# SMS register map
Vendor: Texas Instruments
Peripheral module from a debugger description file (folder omap36xx).
Registers are 32-bit, read-write, reset values left out (the file's numbers can be read two ways) unless marked. A register's access mark holds for its fields unless they carry their own. Offsets are as the file gives them; lines under a group give offsets from that group; [hi:lo] are bit positions; {n}, {i} and the like mark numbered series; 'fields as' and 'values as' point back to an identical list; <NAME> marks a mode.

## SMS
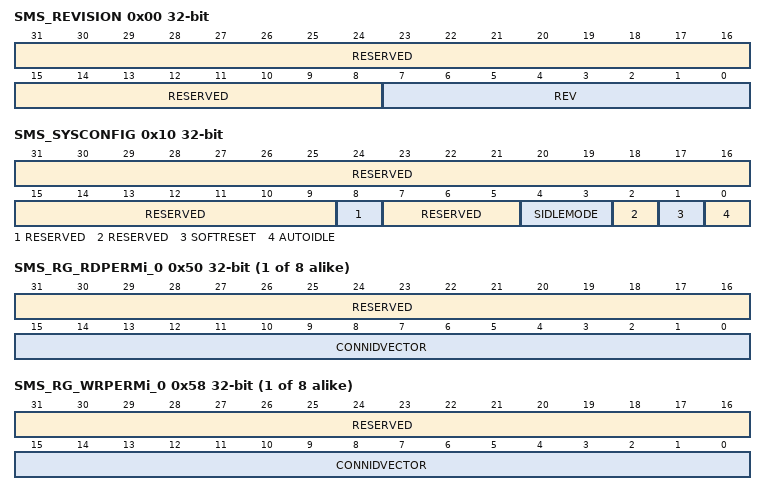
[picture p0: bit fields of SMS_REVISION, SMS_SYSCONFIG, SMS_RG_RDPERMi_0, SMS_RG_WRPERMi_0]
0x00 SMS_REVISION ro — This register contains the IP revision code. IP revision code is defined at design time
  [31:8] RESERVED — Read returns 0.
  [7:0] REV — IP revision code[7:4] Major revision[3:0] Minor revisionExamples: 0x10 for 1.0, 0x21 for 2.1
0x10 SMS_SYSCONFIG — This register controls the various parameters of the Interconnect.
  [31:9] RESERVED — Write 0s for future compatibility. Read returns 0s.
  [8] RESERVED — Write 0s for future compatibility. Read returns 0s.
  [7:5] RESERVED — Write 0s for future compatibility. Read returns 0s.
  [4:3] SIDLEMODE — Power management Req/Ack Control
    0=Force Idle - An idle request is acknowledged unconditionally; 1=No Idle - An idle request is never acknowledged; 2=Smart Idle - Acknowledgment to an idle request is based on the internal activity of the module; 3=Reserved - Do not use
  [2] RESERVED — Write 0s for future compatibility. Read returns 0.
  [1] SOFTRESET — Software reset
    0=Normal mode (no reset applied); 1=Software reset is activated
  [0] AUTOIDLE — Internal interface clock gating strategy
    0=Interface clock is free-running; 1=Automatic interface clock gating strategy is applied, based on the interconnect activity
0x14 SMS_SYSSTATUS ro — This register provides module status, excluding interrupt status info.
  [0] RESETDONE — Internal reset monitoring
    0=Internal module reset is ongoing; 1=Reset complete. The module is ready to be used.
{0x48+0x20*i} SMS_RG_ATTi_{i} (i=0..7) — Request information permission
  [31:0] REQINFO — Request information permissionThe REQINFO field is a bit vector of permissions, one per MReqInfo encoding: NonHost/Host - User/Supervisor - Functional/Debug - Data Transfer/Opcode Fetch
{0x50+0x20*i} SMS_RG_RDPERMi_{i} (i=0..7) — This register provides the list of all initiators that have permission for reading from that memory region.
  [31:16] RESERVED — Write 0s for future compatibility. Read returns 0s.
  [15:0] CONNIDVECTOR — One bit per initiator group. Bit 0 set to 1 means that initiator whose ConnID = 0 has read permission to the protected region i.
{0x58+0x20*i} SMS_RG_WRPERMi_{i} (i=0..7) — This register provides the list of all initiators that have permission for writing to that memory region.
  [31:16] RESERVED — Write 0s for future compatibility. Read returns 0s.
  [15:0] CONNIDVECTOR — One bit per initiator group. Bit 0 set to 1 means that initiator whose ConnID = 0 has write permission to the protected region i.
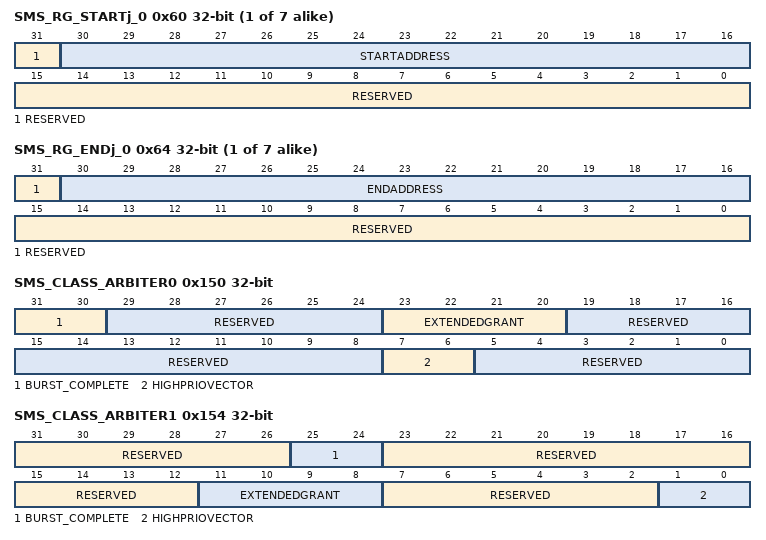
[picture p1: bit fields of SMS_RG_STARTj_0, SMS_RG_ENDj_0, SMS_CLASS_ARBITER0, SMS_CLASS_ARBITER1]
{0x60+0x20*i} SMS_RG_STARTj_{i} (i=0..6) — This register provides the region #j start address (lowest address inside the region), with a 64-KB granularity.
  [31] RESERVED — Write 0s for future compatibility. Read returns 0.
  [30:16] STARTADDRESS — Region #j start address (included in the region)Aligned on 64-KB boundary. [15:0] must be written with 0s. No STARTADDRESS parameter for region 0.
  [15:0] RESERVED — Write 0s for future compatibility. Read returns 0.
{0x64+0x20*i} SMS_RG_ENDj_{i} (i=0..6) — This register provides the region #j end address (lowest address outside the region), with a 64-KB granularity.
  [31] RESERVED — Write 0s for future compatibility. Read returns 0s.
  [30:16] ENDADDRESS — Region #j end address (not included in the region)Aligned on 64-KB boundary. [15:0] must be written with 0s. No ENDADDRESS parameter for region 0.
  [15:0] RESERVED — Write 0s for future compatibility. Read returns 0s.
0x150 SMS_CLASS_ARBITER0 — This register controls the arbitration parameters between the class 0 request groups.
  [31:30] BURST_COMPLETE — Delayed service until burst request complete BurstComplete[k], k= 6 to 7 (BURST-COMPLETE[30] is for group number 6, BURST-COMPLETE[31] is for group number 7)
    0=BURST-COMPLETE_0 (Group #k request to arbiter issued as soon as the first burst request is available); 1=BURST-COMPLETE_1 (Group #k request to arbiter delayed until a complete burst transaction is buffered)
  [29:24] RESERVED — Write 0s for future compatibility. Read returns 0s.
  [23:20] EXTENDEDGRANT — Extended grant service inside a classVector specifying the number of consecutive services a group is granted. 2 bits per group ExtendedGrant[2*k+1,2*k], k = 6 to 7 (EXTENDEDGRANT[21:20] is for group number 6, EXTENDEDGRANT[23:22] is for group number 7)
    1=1 service for group #k when granted; 2=2 services for group #k when granted; 3=3 services for group #k when granted
  [19:8] RESERVED — Write 0s for future compatibility. Read returns 0s.
  [7:6] HIGHPRIOVECTOR — High-priority attribute inside a classVector allocating a higher priority to one of the class members. A single group may be given this attribute at a time. HighPrioVector[k], k= 6 to 7 (HIGHPRIOVECTOR[6] is for group number 6, HIGHPRIOVECTOR[7] is for group number 7)
    0=Group #k has standard priority (LRU based); 1=Group #k has the highest priority over all other class members
  [5:0] RESERVED — Write 0s for future compatibility. Read returns 0s.
0x154 SMS_CLASS_ARBITER1 — This register controls the arbitration parameters between the class 1 request groups.
  [31:26] RESERVED — Write 0s for future compatibility. Read returns 0s.
  [25:24] BURST_COMPLETE — Delayed service until burst request completeBurstComplete[k], k= 0 to 1 (BURST-COMPLETE[24] is for group number 0, BURST-COMPLETE[25] is for group number 1)
    values as SMS_CLASS_ARBITER0.BURST_COMPLETE
  [23:12] RESERVED — Write 0s for future compatibility. Read returns 0s.
  [11:8] EXTENDEDGRANT — Extended grant service inside a classVector specifying the number of consecutive services a group is granted. 2 bits per group ExtendedGrant[2*k+1,2*k], k = 0 to 1 (EXTENDEDGRANT[9:8] is for group number 0, EXTENDEDGRANT[11:10] is for group number 1)
    values as SMS_CLASS_ARBITER0.EXTENDEDGRANT
  [7:2] RESERVED — Write 0s for future compatibility. Read returns 0s.
  [1:0] HIGHPRIOVECTOR — High-priority attribute inside a classVector allocating a higher priority to one of the class members. A single group may be given this attribute at a time. HighPrioVector[k], k= 0 to 1 (HIGHPRIOVECTOR[1] is for group number 1, HIGHPRIOVECTOR[0] is for group number 0)
    values as SMS_CLASS_ARBITER0.HIGHPRIOVECTOR
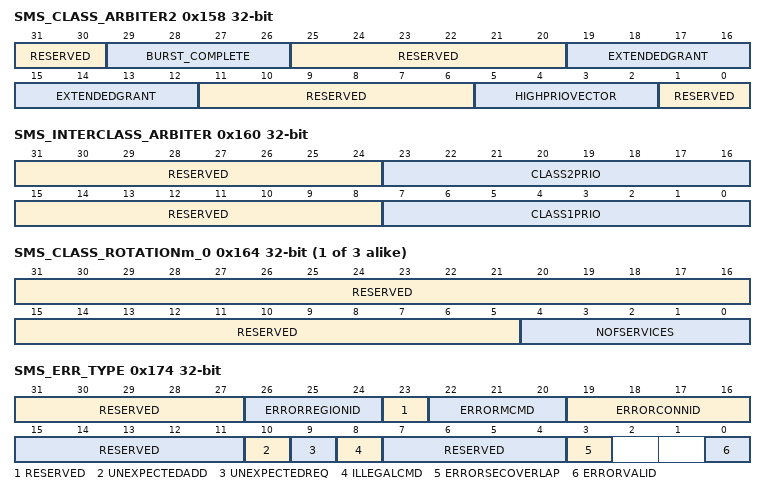
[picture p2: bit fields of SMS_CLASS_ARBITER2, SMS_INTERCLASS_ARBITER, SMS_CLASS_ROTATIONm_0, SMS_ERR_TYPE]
0x158 SMS_CLASS_ARBITER2 — This register controls the arbitration parameters between the class 2 request groups.
  [31:30] RESERVED — Write 0s for future compatibility. Read returns 0s.
  [29:26] BURST_COMPLETE — Delayed service until burst request completeBurstComplete[k], k= 2 to 5 (BURST-COMPLETE[29] is for group number 5, BURST-COMPLETE[28] is for group number 4, BURST-COMPLETE[27] is for group number 3, BURST-COMPLETE[26] is for group number 2)
    values as SMS_CLASS_ARBITER0.BURST_COMPLETE
  [25:20] RESERVED — Write 0s for future compatibility. Read returns 0s.
  [19:12] EXTENDEDGRANT — Vector specifying the number of consecutive services a group is granted. 2 bits per group ExtendedGrant[2*k+1,2*k], k = 2 to 5 (EXTENDEDGRANT[19:18] is for group number 5, EXTENDEDGRANT[17:16] is for group number 4, EXTENDEDGRANT[15:14] is for group number 3, EXTENDEDGRANT[13:12] is for group number 2)
    values as SMS_CLASS_ARBITER0.EXTENDEDGRANT
  [11:6] RESERVED — Write 0s for future compatibility. Read returns 0s.
  [5:2] HIGHPRIOVECTOR — Vector allocating a higher priority to one of the class members. A single group may be given this attribute at a time. HighPrioVector[k], k= 2 to 5 (HIGHPRIOVECTOR[5] is for group number 5, HIGHPRIOVECTOR[4] is for group number 4, HIGHPRIOVECTOR[3] is for group number 3, HIGHPRIOVECTOR[2] is for group number 2)
    values as SMS_CLASS_ARBITER0.HIGHPRIOVECTOR
  [1:0] RESERVED — Write 0s for future compatibility. Read returns 0s.
0x160 SMS_INTERCLASS_ARBITER — This register controls the PWM counter that defines the priority alternation between class 1 and class 2.
  [31:24] RESERVED — Write 0s for future compatibility. Read returns 0s.
  [23:16] CLASS2PRIO — Class 2 high-priority window width (clock cycle count). Do not set to 0x00.
  [15:8] RESERVED — Write 0s for future compatibility. Read returns 0s.
  [7:0] CLASS1PRIO — Class 1 high-priority window width (clock cycle count). Do not set to 0x00.
{0x164+4i} SMS_CLASS_ROTATIONm_{i} (i=0..2) — This register controls the number of consecutive services that is allocated to a thread whose transactions have been split by the rotation engine.
  [31:5] RESERVED — Write 0s for future compatibility. Read returns 0s.
  [4:0] NOFSERVICES — Number of RE split transactions serviced consecutively when the thread gets granted by the arbitration logic.
0x170 SMS_ERR_ADDR ro — This register captures the address of an access that has generated an error.
  [31:0] ERRORADDRESS — Access address that has generated an error (bit 31 is always 0)
0x174 SMS_ERR_TYPE access per field — This register provides additional information about the access that has generated the error.
  [31:27] RESERVED rw — Write 0s for future compatibility. Read returns 0s.
  [26:24] ERRORREGIONID ro — ID of the region that has been illegally accessed0x0: Region 00x1: Region 1...0x7: Region 70x8 to 0xF: reserved
  [23] RESERVED rw — Write 0s for future compatibility. Read returns 0s.
  [22:20] ERRORMCMD ro — Interconnect command that caused the error
  [19:16] ERRORCONNID ro — Identifies the illegal access initiator interconnect ConnID of the illegal access initiator.Refer to the top level documentation of the device using the SMS module
  [15:11] RESERVED rw — Write 0s for future compatibility.Read returns 0s.
  [10] UNEXPECTEDADD rw — Request targeting non-defined rotation contexts (such as contexts 12, 13, 14, or 15) or non-defined L3 Interconnect request signals used for context number decoding.
    0=UNEXPECTEDADD_0_r (No unexpected request received); 0=UNEXPECTEDADD_0_w (No effect); 1=UNEXPECTEDADD_1_r (A request has been received on the interconnect with address decoding targeting rotation contexts 12, 13, 14, or 15, or a signal used for context number decoding was undefined.); 1=UNEXPECTEDADD_1_w (Clear UNEXPECTEDADD bit.)
  [9] UNEXPECTEDREQ rw — Unexpected request received during SMS idle state
    0=UNEXPECTEDREQ_0_r (No unexpected request received); 0=UNEXPECTEDREQ_0_w (No effect); 1=UNEXPECTEDREQ_1_r (A request has been received on the interconnect after the SMS was put in idle mode by the system power manager.); 1=UNEXPECTEDREQ_1_w (Clear the UNEXPECTEDREQ bit field.)
  [8] ILLEGALCMD rw — Illegal command on the L3 interface
    0=ILLEGALCMD_0_r (No illegal command received); 0=ILLEGALCMD_0_w (No effect); 1=ILLEGALCMD_1_r (Illegal command has been received.); 1=ILLEGALCMD_1_w (Clear ILLEGALCMD bit field.)
  [7:4] RESERVED rw — Write 0s for future compatibility.Read returns 0s.
  [3] ERRORSECOVERLAP rw — Protection region overlapping error
    0=ERRORSECOVERLAP_0_r (No overlap violation detected); 0=ERRORSECOVERLAP_0_w (No effect); 1=ERRORSECOVERLAP_1_r (A protection region overlap violation has been detected.); 1=ERRORSECOVERLAP_1_w (Clear ERRORSECOVERLAP bit field.)
  [0] ERRORVALID rw — Error validity status - Must be explicitly cleared with a write transaction
    0=ERRORVALID_0_r (No effect); 0=ERRORVALID_0_w (All error fields no longer valid); 1=ERRORVALID_1_r (Error detected and logged in the other error fields); 1=ERRORVALID_1_w (Clear ERRORVALID bit field)
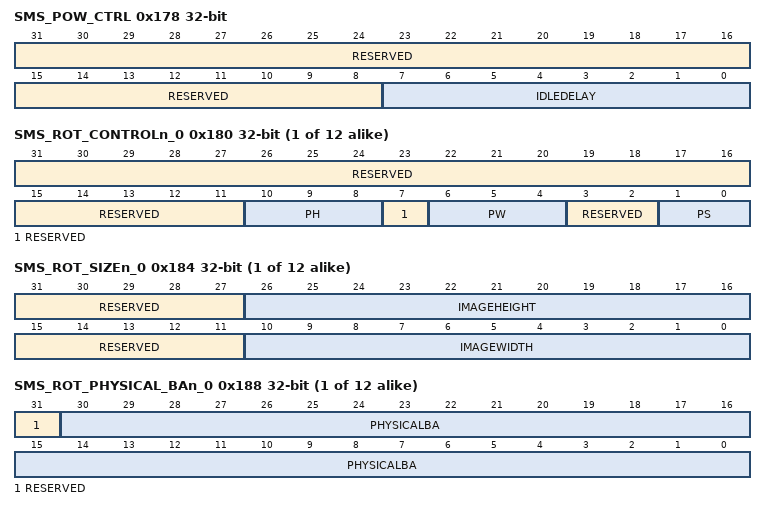
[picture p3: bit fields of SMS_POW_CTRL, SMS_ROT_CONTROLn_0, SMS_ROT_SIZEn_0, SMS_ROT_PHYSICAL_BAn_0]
0x178 SMS_POW_CTRL — This register controls the SMS power management in conjunction with the regular interconnect socket registers.
  [31:8] RESERVED — Write 0s for future compatibility. Read returns 0s.
  [7:0] IDLEDELAY — Delay (expressed in L3 clock cycle units) before autoidle, that is, before disabling the SMS functional clock when no more traffic in the SMS module.
{0x180+0x10*i} SMS_ROT_CONTROLn_{i} (i=0..11) — This register configures the virtual rotated frame buffer module for context #n.
  [31:11] RESERVED — Write 0s for future compatibility. Read returns 0s.
  [10:8] PH — Exponent based 2 value, 2 indicates the page height in bytes for context #n.
  [7] RESERVED — Write 0s for future compatibility. Read returns 0s.
  [6:4] PW — Exponent based 2 value, 2 indicates the page width in bytes for context #n.
  [3:2] RESERVED — Write 0s for future compatibility. Read returns 0s.
  [1:0] PS — Exponent based 2 value, 2 indicates the pixel size in bytes for context #n. A value of 3 is invalid.
{0x184+0x10*i} SMS_ROT_SIZEn_{i} (i=0..11) — This register configures the bank organization for context #n.
  [31:27] RESERVED — Write 0s for future compatibility. Read returns 0s.
  [26:16] IMAGEHEIGHT — Image height in pixels for context #n
  [15:11] RESERVED — Write 0s for future compatibility. Read returns 0s.
  [10:0] IMAGEWIDTH — Image width in pixels for context #n
{0x188+0x10*i} SMS_ROT_PHYSICAL_BAn_{i} (i=0..11) — This register allows to configure the physical base address for context #n.
  [31] RESERVED — Write 0s for future compatibility. Read returns 0s.
  [30:0] PHYSICALBA — Physical base address of the frame buffer for context #n in SDRAM
